# ATSAM4SA16C register map
Vendor: Atmel; File version: 0
CPU: CM4 r0p1, selectable endian, no MPU, no FPU, 0x4 interrupt priority bits, 0x0 interrupts
Registers are 32-bit, read-write, no defined reset value unless marked. A register's access mark holds for its fields unless they carry their own. Offsets are from the block's base; [hi:lo] are bit positions; {n}, {i} and the like mark numbered series.

## SMC — Static Memory Controller
Base 0x400E0000; register names take the prefix SMC_
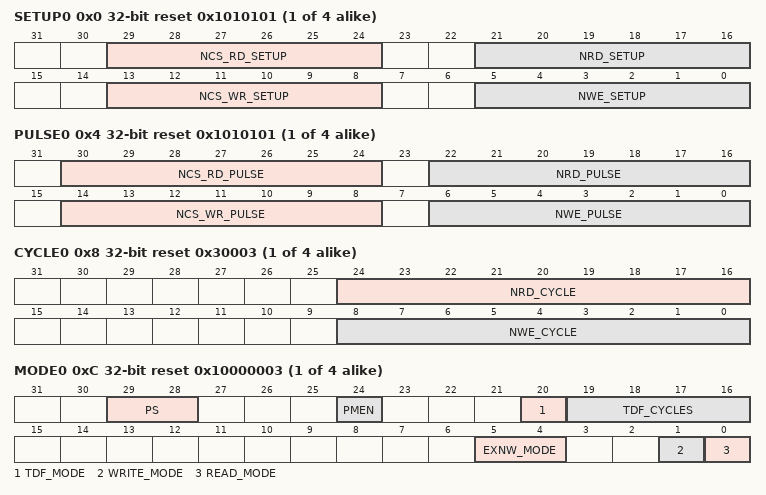
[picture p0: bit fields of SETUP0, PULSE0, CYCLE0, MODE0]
{0x0+0x10*i} SETUP{i} reset 0x1010101 (i=0..3) — SMC Setup Register (CS_number = {i})
  [29:24] NCS_RD_SETUP — NCS Setup Length in READ Access
  [21:16] NRD_SETUP — NRD Setup Length
  [13:8] NCS_WR_SETUP — NCS Setup Length in WRITE Access
  [5:0] NWE_SETUP — NWE Setup Length
{0x4+0x10*i} PULSE{i} reset 0x1010101 (i=0..3) — SMC Pulse Register (CS_number = {i})
  [30:24] NCS_RD_PULSE — NCS Pulse Length in READ Access
  [22:16] NRD_PULSE — NRD Pulse Length
  [14:8] NCS_WR_PULSE — NCS Pulse Length in WRITE Access
  [6:0] NWE_PULSE — NWE Pulse Length
{0x8+0x10*i} CYCLE{i} reset 0x30003 (i=0..3) — SMC Cycle Register (CS_number = {i})
  [24:16] NRD_CYCLE — Total Read Cycle Length
  [8:0] NWE_CYCLE — Total Write Cycle Length
{0xC+0x10*i} MODE{i} reset 0x10000003 (i=0..3) — SMC MODE Register (CS_number = {i})
  [29:28] PS — Page Size
    0=4_BYTE (4-byte page); 1=8_BYTE (8-byte page); 2=16_BYTE (16-byte page); 3=32_BYTE (32-byte page)
  [24] PMEN — Page Mode Enabled
  [20] TDF_MODE — TDF Optimization
  [19:16] TDF_CYCLES — Data Float Time
  [5:4] EXNW_MODE — NWAIT Mode
    0=DISABLED; 2=FROZEN (Frozen Mode); 3=READY (Ready Mode)
  [1] WRITE_MODE
  [0] READ_MODE
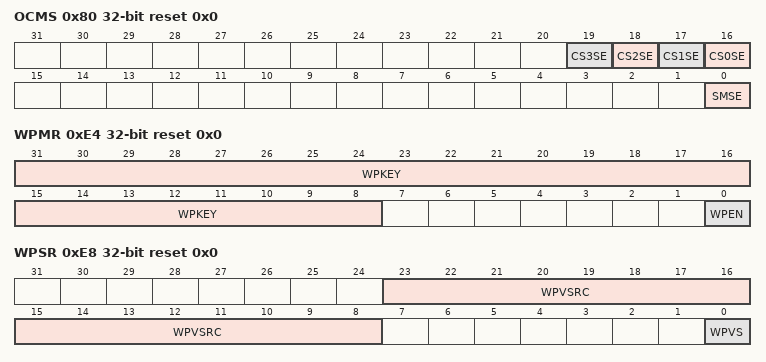
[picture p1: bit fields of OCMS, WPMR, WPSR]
0x80 OCMS reset 0x0 — SMC OCMS MODE Register
  [n+16] CS{n}SE (n=0..3) — Chip Select (x = 0 to 3) Scrambling Enable
  [0] SMSE — Static Memory Controller Scrambling Enable
0x84 KEY1 wo reset 0x0 — SMC OCMS KEY1 Register
  [31:0] KEY1 — Off Chip Memory Scrambling (OCMS) Key Part 1
0x88 KEY2 wo reset 0x0 — SMC OCMS KEY2 Register
  [31:0] KEY2 — Off Chip Memory Scrambling (OCMS) Key Part 2
0xE4 WPMR reset 0x0 — SMC Write Protection Mode Register
  [31:8] WPKEY — Write Protection Key
    0x534D43=PASSWD (Writing any other value in this field aborts the write operation of the WPEN bit. Always reads as 0.)
  [0] WPEN — Write Protect Enable
0xE8 WPSR ro reset 0x0 — SMC Write Protection Status Register
  [23:8] WPVSRC — Write Protection Violation Source
  [0] WPVS — Write Protection Violation Status

## MATRIX — AHB Bus Matrix
Base 0x400E0200
{0x0+4i} MATRIX_MCFG[{i}] (i=0..3) — Master Configuration Register
  [2:0] ULBT — Undefined Length Burst Type
    0=INFINITE (No predicted end of burst is generated and therefore INCR bursts coming from this master cannot be broken.); 1=SINGLE (The undefined length burst is treated as a succession of single access allowing rearbitration at each beat of the INCR burst.); 2=FOUR_BEAT (The undefined length burst is split into a 4-beat bursts allowing rearbitration at each 4-beat burst end.); 3=EIGHT_BEAT (The undefined length burst is split into 8-beat bursts allowing rearbitration at each 8-beat burst end.); 4=SIXTEEN_BEAT (The undefined length burst is split into 16-beat bursts allowing rearbitration at each 16-beat burst end.)
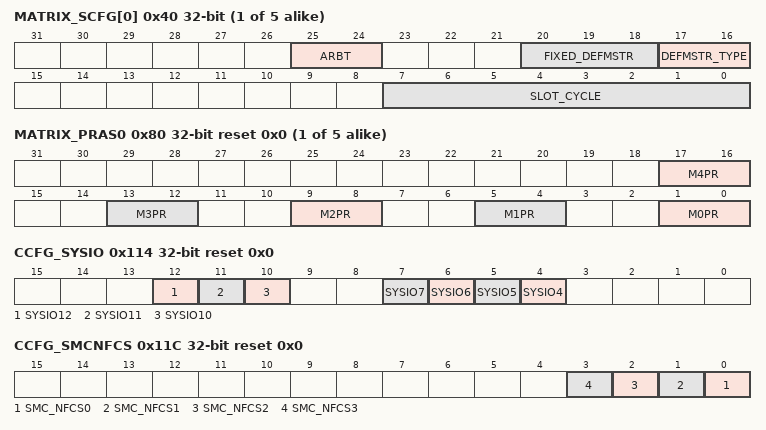
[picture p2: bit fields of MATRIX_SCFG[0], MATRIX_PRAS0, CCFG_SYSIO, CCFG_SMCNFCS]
{0x40+4i} MATRIX_SCFG[{i}] (i=0..4) — Slave Configuration Register
  [25:24] ARBT — Arbitration Type
    0=ROUND_ROBIN (Round-robin arbitration); 1=FIXED_PRIORITY (Fixed priority arbitration)
  [20:18] FIXED_DEFMSTR — Fixed Default Master
  [17:16] DEFMSTR_TYPE — Default Master Type
    0=NO_DEFAULT (At the end of current slave access, if no other master request is pending, the slave is disconnected from all masters.This results in having a one cycle latency for the first access of a burst transfer or for a single access.); 1=LAST (At the end of current slave access, if no other master request is pending, the slave stays connected to the last master having accessed it.This results in not having the one cycle latency when the last master tries to access the slave again.); 2=FIXED (At the end of the current slave access, if no other master request is pending, the slave connects to the fixed master the number that has been written in the FIXED_DEFMSTR field.This results in not having the one cycle latency when the fixed master tries to access the slave again.)
  [7:0] SLOT_CYCLE — Maximum Number of Allowed Cycles for a Burst
{0x80+8i} MATRIX_PRAS{i} reset 0x0 (i=0..4) — Priority Register A for Slave {i}
  [4n+1:4n] M{n}PR (n=0..4) — Master {n} Priority
0x114 CCFG_SYSIO reset 0x0 — System I/O Configuration register
  [12] SYSIO12 — PB12 or ERASE Assignment
  [11] SYSIO11 — PB11 or DDP Assignment
  [10] SYSIO10 — PB10 or DDM Assignment
  [7] SYSIO7 — PB7 or TCK/SWCLK Assignment
  [6] SYSIO6 — PB6 or TMS/SWDIO Assignment
  [5] SYSIO5 — PB5 or TDO/TRACESWO Assignment
  [4] SYSIO4 — PB4 or TDI Assignment
0x11C CCFG_SMCNFCS reset 0x0 — SMC Chip Select NAND Flash Assignment Register
  [n] SMC_NFCS{n} (n=0..3) — SMC NAND Flash Chip Select {n} Assignment
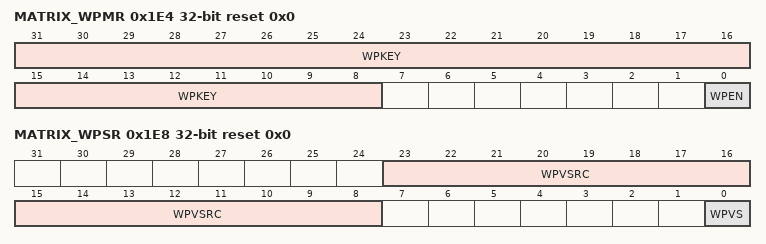
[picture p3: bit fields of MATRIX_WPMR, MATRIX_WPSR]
0x1E4 MATRIX_WPMR reset 0x0 — Write Protection Mode Register
  [31:8] WPKEY — Write Protect Key
    0x4D4154=PASSWD (Writing any other value in this field aborts the write operation of the WPEN bit. Always reads as 0.)
  [0] WPEN — Write Protection Enable
0x1E8 MATRIX_WPSR ro reset 0x0 — Write Protection Status Register
  [23:8] WPVSRC — Write Protection Violation Source
  [0] WPVS — Write Protection Violation Status
